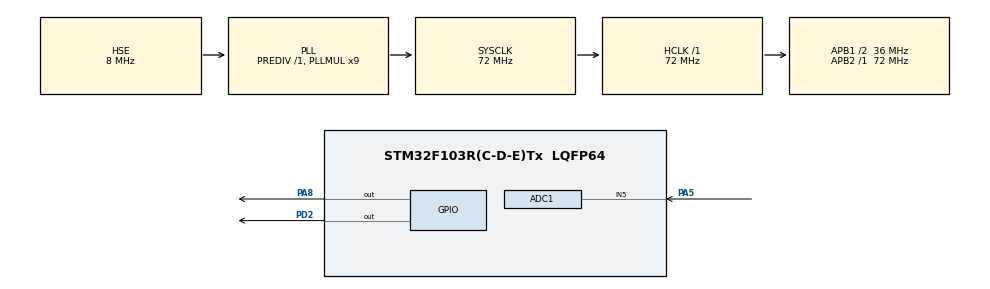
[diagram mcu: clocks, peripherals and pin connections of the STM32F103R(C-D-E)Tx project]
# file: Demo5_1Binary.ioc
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ADC1.Channel-0\#ChannelRegularConversion=ADC_CHANNEL_5
ADC1.ExternalTrigConv=ADC_EXTERNALTRIGCONV_T3_TRGO
ADC1.NbrOfConversionFlag=1
ADC1.Rank-0\#ChannelRegularConversion=1
ADC1.SamplingTime-0\#ChannelRegularConversion=ADC_SAMPLETIME_1CYCLE_5
ADC1.master=1
FREERTOS.BinarySemaphores01=BinSem_DataReady,Dynamic,NULL
FREERTOS.Tasks01=Task_Show,24,128,AppTask_Show,Default,NULL,Dynamic,NULL,NULL
Mcu.Family=STM32F1
Mcu.Name=STM32F103R(C-D-E)Tx
Mcu.Package=LQFP64
NVIC.ADC1_2_IRQn=true\:5\:0\:false\:false\:true\:true\:true\:true\:true
NVIC.PriorityGroup=NVIC_PRIORITYGROUP_4
NVIC.TIM6_IRQn=true\:15\:0\:false\:false\:true\:false\:false\:true\:true
NVIC.TimeBase=TIM6_IRQn
NVIC.TimeBaseIP=TIM6
PA13.Mode=Serial_Wire
PA13.Signal=SYS_JTMS-SWDIO
PA14.Mode=Serial_Wire
PA14.Signal=SYS_JTCK-SWCLK
PA5.Signal=ADCx_IN5
PA8.Signal=GPIO_Output
PC14-OSC32_IN.Mode=LSE-External-Oscillator
PC14-OSC32_IN.Signal=RCC_OSC32_IN
PC15-OSC32_OUT.Mode=LSE-External-Oscillator
PC15-OSC32_OUT.Signal=RCC_OSC32_OUT
PD0-OSC_IN.Mode=HSE-External-Oscillator
PD0-OSC_IN.Signal=RCC_OSC_IN
PD1-OSC_OUT.Mode=HSE-External-Oscillator
PD1-OSC_OUT.Signal=RCC_OSC_OUT
PD2.Signal=GPIO_Output
ProjectManager.HeapSize=0x200
ProjectManager.StackSize=0x400
ProjectManager.TargetToolchain=SW4STM32
RCC.ADCPresc=RCC_ADCPCLK2_DIV6
RCC.AHBFreq_Value=72000000
RCC.APB1CLKDivider=RCC_HCLK_DIV2
RCC.APB1Freq_Value=36000000
RCC.APB1TimFreq_Value=72000000
RCC.APB2Freq_Value=72000000
RCC.APB2TimFreq_Value=72000000
RCC.HCLKFreq_Value=72000000
RCC.PLLMUL=RCC_PLL_MUL9
RCC.PLLSourceVirtual=RCC_PLLSOURCE_HSE
RCC.SYSCLKFreq_VALUE=72000000
RCC.SYSCLKSource=RCC_SYSCLKSOURCE_PLLCLK
RCC.USBFreq_Value=72000000
SH.ADCx_IN5.0=ADC1_IN5,IN5
TIM3.Period=500
TIM3.Prescaler=7199
TIM3.TIM_MasterOutputTrigger=TIM_TRGO_UPDATE
VP_FREERTOS_VS_CMSIS_V2.Mode=CMSIS_V2
VP_SYS_VS_tim6.Mode=TIM6
VP_TIM3_VS_ClockSourceINT.Mode=Internal
board=custom

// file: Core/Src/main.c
/* USER CODE BEGIN Header */
/**
  ******************************************************************************
  * @file           : main.c
  * @brief          : Main program body
  ******************************************************************************
  * @attention
  *
  * Copyright (c) 2022 STMicroelectronics.
  * All rights reserved.
  *
  * This software is licensed under terms that can be found in the LICENSE file
  * in the root directory of this software component.
  * If no LICENSE file comes with this software, it is provided AS-IS.
  *
  ******************************************************************************
  */
/* USER CODE END Header */
#include "main.h"
#include "cmsis_os.h"
#include "adc.h"
#include "tim.h"
#include "gpio.h"

/* USER CODE BEGIN Includes */
#include "lcd.h"
/* USER CODE END Includes */

void SystemClock_Config(void);
void MX_FREERTOS_Init(void);

int main(void)
{

  /* MCU Configuration--------------------------------------------------------*/

  /* Reset of all peripherals, Initializes the Flash interface and the Systick. */
  HAL_Init();

  /* USER CODE BEGIN Init */
  LCD_Init();
  /* USER CODE END Init */

  /* Configure the system clock */
  SystemClock_Config();

  /* Initialize all configured peripherals */
  MX_GPIO_Init();
  MX_ADC1_Init();
  MX_TIM3_Init();
  /* USER CODE BEGIN 2 */
  LCD_ShowString(20,20,160,24,16,(uint8_t *)"Demo5_1Binary");
  HAL_ADC_Start_IT(&hadc1);
  HAL_TIM_Base_Start_IT(&htim3);
  /* USER CODE END 2 */

  /* Init scheduler */
  osKernelInitialize();  /* Call init function for freertos objects (in freertos.c) */
  MX_FREERTOS_Init();

  /* Start scheduler */
  osKernelStart();

  /* We should never get here as control is now taken by the scheduler */
  /* Infinite loop */
  while (1)
  {

  }
}

void SystemClock_Config(void)
{
  RCC_OscInitTypeDef RCC_OscInitStruct = {0};
  RCC_ClkInitTypeDef RCC_ClkInitStruct = {0};
  RCC_PeriphCLKInitTypeDef PeriphClkInit = {0};

  /** Initializes the RCC Oscillators according to the specified parameters
  * in the RCC_OscInitTypeDef structure.
  */
  RCC_OscInitStruct.OscillatorType = RCC_OSCILLATORTYPE_HSE;
  RCC_OscInitStruct.HSEState = RCC_HSE_ON;
  RCC_OscInitStruct.HSEPredivValue = RCC_HSE_PREDIV_DIV1;
  RCC_OscInitStruct.HSIState = RCC_HSI_ON;
  RCC_OscInitStruct.PLL.PLLState = RCC_PLL_ON;
  RCC_OscInitStruct.PLL.PLLSource = RCC_PLLSOURCE_HSE;
  RCC_OscInitStruct.PLL.PLLMUL = RCC_PLL_MUL9;
  if (HAL_RCC_OscConfig(&RCC_OscInitStruct) != HAL_OK)
  {
    Error_Handler();
  }

  /** Initializes the CPU, AHB and APB buses clocks
  */
  RCC_ClkInitStruct.ClockType = RCC_CLOCKTYPE_HCLK|RCC_CLOCKTYPE_SYSCLK
                              |RCC_CLOCKTYPE_PCLK1|RCC_CLOCKTYPE_PCLK2;
  RCC_ClkInitStruct.SYSCLKSource = RCC_SYSCLKSOURCE_PLLCLK;
  RCC_ClkInitStruct.AHBCLKDivider = RCC_SYSCLK_DIV1;
  RCC_ClkInitStruct.APB1CLKDivider = RCC_HCLK_DIV2;
  RCC_ClkInitStruct.APB2CLKDivider = RCC_HCLK_DIV1;

  if (HAL_RCC_ClockConfig(&RCC_ClkInitStruct, FLASH_LATENCY_2) != HAL_OK)
  {
    Error_Handler();
  }
  PeriphClkInit.PeriphClockSelection = RCC_PERIPHCLK_ADC;
  PeriphClkInit.AdcClockSelection = RCC_ADCPCLK2_DIV6;
  if (HAL_RCCEx_PeriphCLKConfig(&PeriphClkInit) != HAL_OK)
  {
    Error_Handler();
  }
}

void HAL_TIM_PeriodElapsedCallback(TIM_HandleTypeDef *htim)
{
  if (htim->Instance == TIM6) {
    HAL_IncTick();
  }
}

void Error_Handler(void)
{
  __disable_irq();
  while (1)
  {
  }
}

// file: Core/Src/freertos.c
/* USER CODE BEGIN Header */
/**
  ******************************************************************************
  * File Name          : freertos.c
  * Description        : Code for freertos applications
  ******************************************************************************
  * @attention
  *
  * Copyright (c) 2022 STMicroelectronics.
  * All rights reserved.
  *
  * This software is licensed under terms that can be found in the LICENSE file
  * in the root directory of this software component.
  * If no LICENSE file comes with this software, it is provided AS-IS.
  *
  ******************************************************************************
  */
/* USER CODE END Header */

#include "FreeRTOS.h"
#include "task.h"
#include "main.h"
#include "cmsis_os.h"

/* USER CODE BEGIN Includes */
#include "semphr.h"
#include "lcd.h"
/* USER CODE END Includes */

/* USER CODE BEGIN PD */
uint32_t adc_value;
/* USER CODE END PD */

/* Definitions for Task_Show */
osThreadId_t Task_ShowHandle;
const osThreadAttr_t Task_Show_attributes = {
  .name = "Task_Show",
  .stack_size = 128 * 4,
  .priority = (osPriority_t) osPriorityNormal,
};
/* Definitions for BinSem_DataReady */
osSemaphoreId_t BinSem_DataReadyHandle;
const osSemaphoreAttr_t BinSem_DataReady_attributes = {
  .name = "BinSem_DataReady"
};

void AppTask_Show(void *argument);

void MX_FREERTOS_Init(void); /* (MISRA C 2004 rule 8.1) */

void MX_FREERTOS_Init(void) {

  /* Create the semaphores(s) */
  /* creation of BinSem_DataReady */
  BinSem_DataReadyHandle = osSemaphoreNew(1, 1, &BinSem_DataReady_attributes);

  /* Create the thread(s) */
  /* creation of Task_Show */
  Task_ShowHandle = osThreadNew(AppTask_Show, NULL, &Task_Show_attributes);

}

void AppTask_Show(void *argument)
{
  /* USER CODE BEGIN AppTask_Show */
  LCD_ShowString(20,50,160,24,16,(uint8_t *)"ADC_Value= ");
  LCD_ShowString(20,80,160,24,16,(uint8_t *)"Voltage(mV)= ");
  POINT_COLOR=RED;
  /* Infinite loop */
  for(;;)
  {
    if(xSemaphoreTake(BinSem_DataReadyHandle,portMAX_DELAY)==pdTRUE)
    {
        uint32_t tmpValue=adc_value;
        LCD_ShowNum(180,50,adc_value,5,16);
        uint32_t Volt=3300*tmpValue;
        Volt=Volt>>12;
        LCD_ShowNum(180,80,Volt,5,16);
    }

    osDelay(1);
  }
  /* USER CODE END AppTask_Show */
}

/* USER CODE BEGIN Application */

void HAL_ADC_ConvCpltCallback(ADC_HandleTypeDef* hadc)
{
    if(hadc->Instance==ADC1)
    {
        adc_value= HAL_ADC_GetValue(hadc);
        BaseType_t highTaskWoken=pdFALSE;
        if(BinSem_DataReadyHandle!=NULL)
        {
            xSemaphoreGiveFromISR(BinSem_DataReadyHandle,&highTaskWoken);
            portYIELD_FROM_ISR(highTaskWoken);
        }
    }
}
/* USER CODE END Application */
